# RL6955_IP_SVD register map
Vendor: Realtek
Registers are 32-bit, read-write, reset 0x0 unless marked. A register's access mark holds for its fields unless they carry their own. Offsets are from the block's base; [hi:lo] are bit positions; lines under a group give offsets from that group; {n}, {i} and the like mark numbered series.

## PINMUX_REG
Base 0x41000800
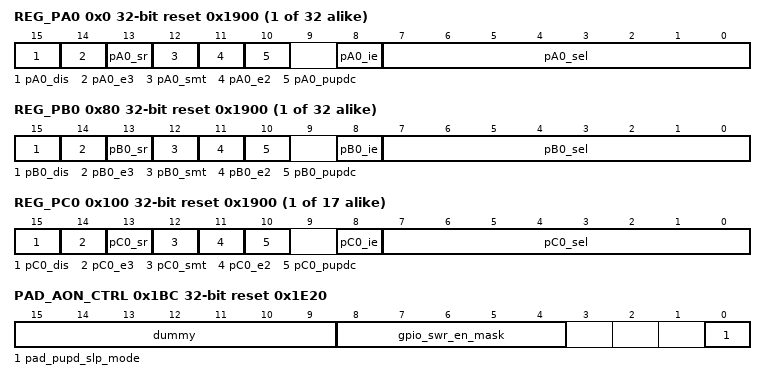
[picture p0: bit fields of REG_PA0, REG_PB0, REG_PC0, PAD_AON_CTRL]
{0x0+4i} REG_PA{i} reset 0x1900 (i=0..31)
  [15] pA{i}_dis — PAD shutdown, only when the whole group's dis signals are all 1, the PAD SHDN will pull down to shutdown the group pad. 1. disable pad 0. enable pad
  [14] pA{i}_e3 — PAD driving ability control. 0: low 1: high The actual driving current is depend on pad type.
  [13] pA{i}_sr — PAD slew rate control. 1: slow 0: fast
  [12] pA{i}_smt — PAD Schmit control
  [11] pA{i}_e2 — PAD driving ability control. 0: low 1: high The actual driving current is depend on pad type.
  [10] pA{i}_pupdc — Some pad may have two type of PU/PD resistor, this bit can select it. 1: small resistor 0: big resistor
  [8] pA{i}_ie — PAD input enable control
  [7:0] pA{i}_sel — PAD pinmux function ID selection
{0x80+4i} REG_PB{i} reset 0x1900 (i=0..31)
  [15] pB{i}_dis — PAD shutdown, only when the whole group's dis signals are all 1, the PAD SHDN will pull down to shutdown the group pad. 1. disable pad 0. enable pad
  [14] pB{i}_e3 — PAD driving ability control. 0: low 1: high The actual driving current is depend on pad type.
  [13] pB{i}_sr — PAD slew rate control. 1: slow 0: fast
  [12] pB{i}_smt — PAD Schmit control
  [11] pB{i}_e2 — PAD driving ability control. 0: low 1: high The actual driving current is depend on pad type.
  [10] pB{i}_pupdc — Some pad may have two type of PU/PD resistor, this bit can select it. 1: small resistor 0: big resistor
  [8] pB{i}_ie — PAD input enable control
  [7:0] pB{i}_sel — PAD pinmux function ID selection
{0x100+4i} REG_PC{i} reset 0x1900 (i=0..16)
  [15] pC{i}_dis — PAD shutdown, only when the whole group's dis signals are all 1, the PAD SHDN will pull down to shutdown the group pad. 1. disable pad 0. enable pad
  [14] pC{i}_e3 — PAD driving ability control. 0: low 1: high The actual driving current is depend on pad type.
  [13] pC{i}_sr — PAD slew rate control. 1: slow 0: fast
  [12] pC{i}_smt — PAD Schmit control
  [11] pC{i}_e2 — PAD driving ability control. 0: low 1: high The actual driving current is depend on pad type.
  [10] pC{i}_pupdc — Some pad may have two type of PU/PD resistor, this bit can select it. 1: small resistor 0: big resistor
  [8] pC{i}_ie — PAD input enable control
  [7:0] pC{i}_sel — PAD pinmux function ID selection
0x180 PAD_PU_1 reset 0x40004020
  [31:0] pa_pu — PAD pull up enable when system is in active.
0x184 PAD_PU_2
  [31:0] pb_pu — PAD pull up enable when system is in active.
0x188 PAD_PU_3 reset 0x7000
  [31:0] pc_pu — PAD pull up enable when system is in active.
0x190 PAD_PD_1
  [31:0] pa_pd — PAD pull down enable when system is in active.
0x194 PAD_PD_2
  [31:0] pb_pd — PAD pull down enable when system is in active.
0x198 PAD_PD_3
  [31:0] pc_pd — PAD pull down enable when system is in active.
0x1A0 PAD_PU_SLP_1 reset 0x40004020
  [31:0] pa_pu_slp — PAD pull up enable when system is in sleep.
0x1A4 PAD_PU_SLP_2
  [31:0] pb_pu_slp — PAD pull up enable when system is in sleep.
0x1A8 PAD_PU_SLP_3 reset 0x7000
  [31:0] pc_pu_slp — PAD pull up enable when system is in sleep.
0x1B0 PAD_PD_SLP_1
  [31:0] pa_pd_slp — PAD pull down enable when system is in sleep.
0x1B4 PAD_PD_SLP_2
  [31:0] pb_pd_slp — PAD pull down enable when system is in sleep.
0x1B8 PAD_PD_SLP_3
  [31:0] pc_pd_slp — PAD pull down enable when system is in sleep.
0x1BC PAD_AON_CTRL reset 0x1E20
  [15:9] dummy
  [8:4] gpio_swr_en_mask — Regu pmc will set one of aon pin to pullup/pulldn to control external SWR. 5'b00001: PC10 5'b00010: PC11 5'b00100: PC12 5'b01000: PC13 5'b10000: PC14
  [0] pad_pupd_slp_mode — pad pupd sleep mode seletion . Note:this bit used in pmc , don't change this addr
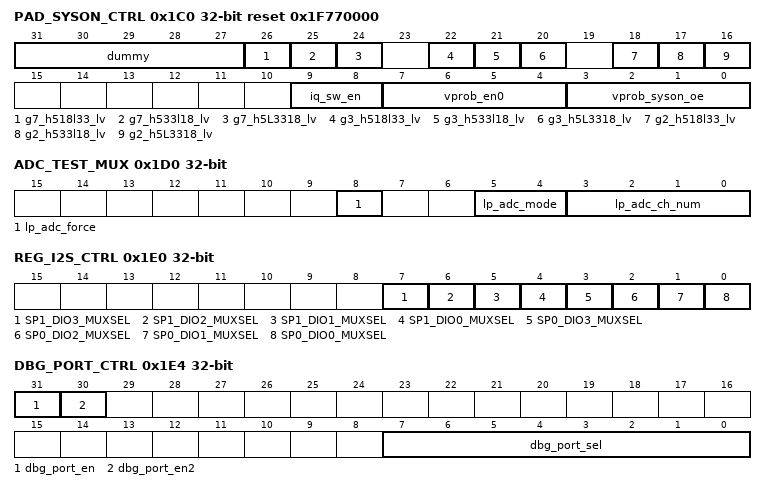
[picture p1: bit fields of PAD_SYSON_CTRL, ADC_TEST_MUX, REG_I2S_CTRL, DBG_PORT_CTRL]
0x1C0 PAD_SYSON_CTRL reset 0x1F770000
  [31:27] dummy
  [26] g7_h518l33_lv
  [25] g7_h533l18_lv
  [24] g7_h5L3318_lv
  [22] g3_h518l33_lv
  [21] g3_h533l18_lv
  [20] g3_h5L3318_lv
  [18] g2_h518l33_lv
  [17] g2_h533l18_lv
  [16] g2_h5L3318_lv — VDDPST=5V H533L18 = 1 H518L33 = 1 H5L3318 = 1 VDDPST=3.3V H533L18 = 1 H518L33 = 0 H5L3318 = 0 VDDPST=1.8V H533L18 = 0 H518L33 = 1 H5L3318 = 0 when PAD SHUTDOWN, pad will ISO this three value to 111 for safety .
  [9:8] iq_sw_en — rfafe 5v sw enable, active 1 [0]: G3 group sw [1]: G7 group sw
  [7:4] vprob_en0 — pad vprob function enable
  [3:0] vprob_syson_oe — vprob source select, msut one-hot [0]: AON_OTP power [1]: SOC power [2]: BT power [3]: RSVD
0x1D0 ADC_TEST_MUX
  [8] lp_adc_force — force sw select instead of pinmux input when adc test mode 1:using [5:0] for adc channel / mode select 0:using io input for adc channel / mode
  [5:4] lp_adc_mode — sw_select adc mode
  [3:0] lp_adc_ch_num — sw select adc test channel
0x1E0 REG_I2S_CTRL
  [7] SP1_DIO3_MUXSEL — SPORT1 DIO3 function mux 0: DIN_3 func 1: DOUT_0 func
  [6] SP1_DIO2_MUXSEL — SPORT1 DIO2 function mux 0: DIN_2 func 1: DOUT_1 func
  [5] SP1_DIO1_MUXSEL — SPORT1 DIO1 function mux 0: DIN_1 func 1: DOUT_2 func
  [4] SP1_DIO0_MUXSEL — SPORT1 DIO0 function mux 0: DIN_0 func 1: DOUT_3 func
  [3] SP0_DIO3_MUXSEL — SPORT0 DIO3 function mux 0: DIN_3 func 1: DOUT_0 func
  [2] SP0_DIO2_MUXSEL — SPORT0 DIO2 function mux 0: DIN_2 func 1: DOUT_1 func
  [1] SP0_DIO1_MUXSEL — SPORT0 DIO1 function mux 0: DIN_1 func 1: DOUT_2 func
  [0] SP0_DIO0_MUXSEL — SPORT0 DIO0 function mux 0: DIN_0 func 1: DOUT_3 func
0x1E4 DBG_PORT_CTRL
  [31] dbg_port_en, [30] dbg_port_en2, [7:0] dbg_port_sel
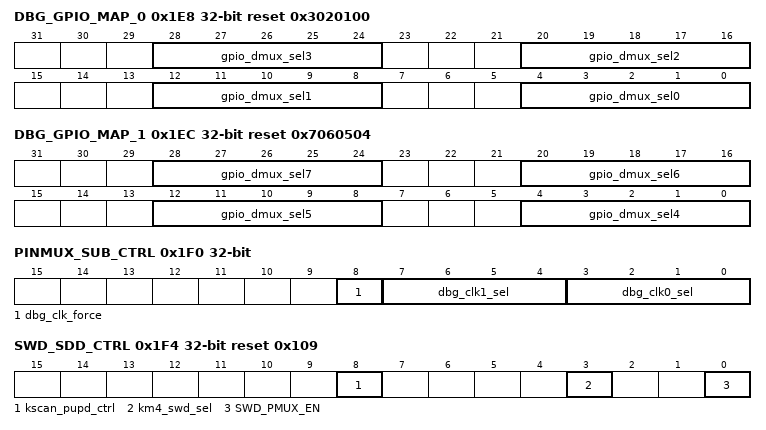
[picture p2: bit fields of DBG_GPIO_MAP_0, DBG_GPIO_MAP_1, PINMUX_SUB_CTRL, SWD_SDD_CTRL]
0x1E8 DBG_GPIO_MAP_0 reset 0x3020100
  [8n+4:8n] gpio_dmux_sel{n} (n=0..3)
0x1EC DBG_GPIO_MAP_1 reset 0x7060504
  [8n-28:8n-32] gpio_dmux_sel{n} (n=4..7)
0x1F0 PINMUX_SUB_CTRL
  [8] dbg_clk_force — Force debug clock divider enable if testmode in clock debug ICFG. This maybe used when EXT_CLK_OUT was used.
  [7:4] dbg_clk1_sel — debug clock1 in CLOCK testmode 0: xtal 40M 1: xtal 20M 2: xtal 2M 3: xtal lps 312.5K 4: sdm_32.768k 5: sdm_1Hz 6.usb pll div 7.sys pll div 8: osc131k 9: osc4M 10: osc100K 11: RMII gmac 50M
  [3:0] dbg_clk0_sel — debug clock1 in CLOCK testmode 0: xtal 40M 1: xtal 20M 2: xtal 2M 3: xtal lps 312.5K 4: sdm_32.768k 5: sdm_1Hz 6.usb pll div 7.sys pll div 8: osc131k 9: osc4M 10: osc100K 11: RMII gmac 50M
0x1F4 SWD_SDD_CTRL reset 0x109
  [8] kscan_pupd_ctrl — enable kscan pupd hw control logic, active 1
  [3] km4_swd_sel — Toggle this bit will switch shared SWD port, this bit only accessed by KM4. Default is KM4 SWD, if km4 toggle this bit , SWD port will switch to KR4
  [0] SWD_PMUX_EN — 1: Force enable share SWD pinmux function 0: Disable
0x1FC PAD_REG_DUMMY_0 reset 0xFFFF
  [31:0] dummy — HW used only , these are for reserved.
